# USBHS register map
Vendor: Texas Instruments
Peripheral module from a debugger description file (folder omap36xx).
Registers are 32-bit, access per field, reset 0x1 unless marked. A register's access mark holds for its fields unless they carry their own. Offsets are as the file gives them; lines under a group give offsets from that group; [hi:lo] are bit positions; {n}, {i} and the like mark numbered series; 'fields as' and 'values as' point back to an identical list; <NAME> marks a mode.

## USBHS
0x400 OTG_REVISION ro reset 0x0 (reset mask 0xFFFFFF00) — Standard USB OTG HS core revision number
  [7:0] OTG_REVISION — Revision number, BCD-encoded
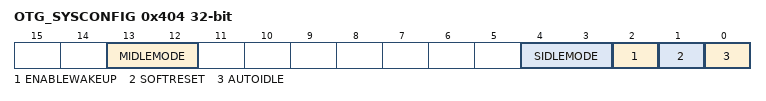
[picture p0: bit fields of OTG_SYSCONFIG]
0x404 OTG_SYSCONFIG — Standard configuration
  [13:12] MIDLEMODE rw — Master interface power management control. Standby/wait control
    0=Force Standby mode. Mstandby asserted unconditionally; 1=No standby mode. Mstandby never asserted.; 2=Smart standby mode. Mstandby asserted when no more activity on the USB master.
  [4:3] SIDLEMODE rw — Slave interface power management control. Req/ack control
    0=Force Idle mode. Sidleack asserted after Midlereq assertion; 1=No idle mode. Sidleack never asserted.; 2=SmartIdle mode. Sidleack asserted after Midlereq assertion when no more activity on the USB.
  [2] ENABLEWAKEUP rw — Enable wakeup capability
    0=Wakeup disabled; 1=Wakeup enabled
  [1] SOFTRESET rw — Software reset bit
    1=Starts softreset sequence
  [0] AUTOIDLE rw — Autoidle bit
    0=Clock always running; 1=When no activity on L3 interconnect, clock is cut off
0x408 OTG_SYSSTATUS ro — OCP standard status
  [0] RESETDONE
    0=RESETDONE_0_r (On going reset); 1=RESETDONE_1_r (Reset is finished.)
0x40C OTG_INTERFSEL — USB OTG HS interface selection
  [1:0] PHYSEL rw — PHY interface selection
    0=PHY interface is 8-bit, UTMI+ level 3. Not supported in the device.; 1=PHY interface is 12-pin, 8-bit SDR ULPI; 2=PHY interface is 8-pin, 4-bit DDR ULPI. Not supported in the device.
0x410 OTG_SIMENABLE reset 0x0 — Enable simulation acceleration features.WARNING: For simulations only, since those features have an impact on USB protocol.
  [0] TM1 rw — Test Mode 1 enabling (timer shortcuts)
0x414 OTG_FORCESTDBY — Enabling MSTANDBY in FORCESTANDBY mode.
  [0] ENABLEFORCE rw — Enabling MSTANDBY to go high
0x418 OTG_BIGENDIAN reset 0x0 — Enable BIG ENDIANESS for OCP MASTER
  [0] BIG_ENDIAN rw — Enable BIG ENDIAN in OCP MASTER0x0 Little Endian . 0x1 Big Endian .
